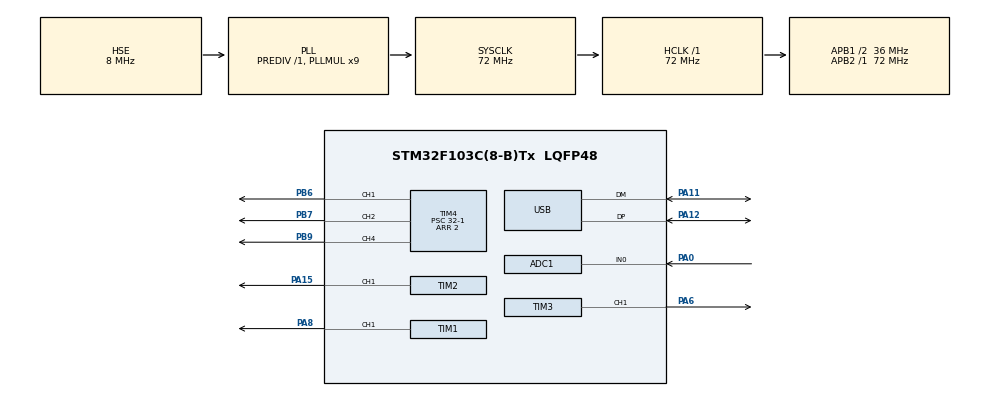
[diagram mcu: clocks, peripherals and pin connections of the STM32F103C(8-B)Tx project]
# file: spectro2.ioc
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ADC1.Channel-4\#ChannelRegularConversion=ADC_CHANNEL_0
ADC1.ContinuousConvMode=DISABLE
ADC1.DataAlign=ADC_DATAALIGN_RIGHT
ADC1.DiscontinuousConvMode=DISABLE
ADC1.EnableAnalogWatchDog=false
ADC1.EnableRegularConversion=ENABLE
ADC1.ExternalTrigConv=ADC_EXTERNALTRIGCONV_T4_CC4
ADC1.ExternalTrigConvEdgeChoice=RISING
ADC1.InjNumberOfConversion=0
ADC1.NbrOfConversion=1
ADC1.NbrOfConversionFlag=1
ADC1.Rank-4\#ChannelRegularConversion=1
ADC1.SamplingTime-4\#ChannelRegularConversion=ADC_SAMPLETIME_1CYCLE_5
ADC1.ScanConvMode=ADC_SCAN_DISABLE
ADC1.master=1
Dma.ADC1.0.Direction=DMA_PERIPH_TO_MEMORY
Dma.ADC1.0.Instance=DMA1_Channel1
Dma.ADC1.0.MemDataAlignment=DMA_MDATAALIGN_HALFWORD
Dma.ADC1.0.MemInc=DMA_MINC_ENABLE
Dma.ADC1.0.Mode=DMA_NORMAL
Dma.ADC1.0.PeriphDataAlignment=DMA_PDATAALIGN_HALFWORD
Dma.ADC1.0.PeriphInc=DMA_PINC_DISABLE
Dma.ADC1.0.Priority=DMA_PRIORITY_LOW
Dma.Request0=ADC1
Mcu.Family=STM32F1
Mcu.Name=STM32F103C(8-B)Tx
Mcu.Package=LQFP48
NVIC.DMA1_Channel1_IRQn=true\:0\:0\:false\:false\:true
NVIC.PriorityGroup=NVIC_PRIORITYGROUP_4
NVIC.USB_LP_CAN1_RX0_IRQn=true\:0\:0\:false\:false\:true
PA0-WKUP.Signal=ADCx_IN0
PA11.Mode=Device
PA11.Signal=USB_DM
PA12.Mode=Device
PA12.Signal=USB_DP
PA15.Signal=S_TIM2_CH1_ETR
PA6.Signal=S_TIM3_CH1
PA8.Signal=S_TIM1_CH1
PB6.Signal=S_TIM4_CH1
PB7.Signal=S_TIM4_CH2
PB9.Signal=S_TIM4_CH4
PD0-OSC_IN.Mode=HSE-External-Oscillator
PD0-OSC_IN.Signal=RCC_OSC_IN
PD1-OSC_OUT.Mode=HSE-External-Oscillator
PD1-OSC_OUT.Signal=RCC_OSC_OUT
ProjectManager.HeapSize=0x200
ProjectManager.StackSize=0x400
ProjectManager.TargetToolchain=MDK-ARM V5
RCC.ADCPresc=RCC_ADCPCLK2_DIV8
RCC.AHBFreq_Value=72000000
RCC.APB1CLKDivider=RCC_HCLK_DIV2
RCC.APB1Freq_Value=36000000
RCC.APB1TimFreq_Value=72000000
RCC.APB2Freq_Value=72000000
RCC.APB2TimFreq_Value=72000000
RCC.HCLKFreq_Value=72000000
RCC.HSIState=RCC_HSI_ON
RCC.PLLMUL=RCC_PLL_MUL9
RCC.PLLSourceVirtual=RCC_PLLSOURCE_HSE
RCC.SYSCLKFreq_VALUE=72000000
RCC.SYSCLKSource=RCC_SYSCLKSOURCE_PLLCLK
RCC.USBFreq_Value=48000000
RCC.USBPrescaler=RCC_USBCLKSOURCE_PLL_DIV1_5
SH.ADCx_IN0.0=ADC1_IN0,IN0
SH.S_TIM1_CH1.0=TIM1_CH1,PWM Generation1 CH1
SH.S_TIM2_CH1_ETR.0=TIM2_CH1,PWM Generation1 CH1
SH.S_TIM3_CH1.0=TIM3_CH1,PWM Generation1 CH1
SH.S_TIM4_CH1.0=TIM4_CH1,PWM Generation1 CH1
SH.S_TIM4_CH2.0=TIM4_CH2,PWM Generation2 CH2
SH.S_TIM4_CH4.0=TIM4_CH4,Forced Output4 CH4
TIM1.ClockDivision=TIM_CLOCKDIVISION_DIV1
TIM1.Period=2000-1
TIM1.Prescaler=36000-1
TIM1.Pulse-PWM\ Generation1\ CH1=50
TIM1.TIM_MasterOutputTrigger=TIM_TRGO_UPDATE
TIM1.TIM_MasterSlaveMode=TIM_MASTERSLAVEMODE_ENABLE
TIM2.OCPolarity_1=TIM_OCPOLARITY_LOW
TIM2.Period=200-1
TIM2.Prescaler=36-1
TIM2.Pulse-PWM\ Generation1\ CH1=50
TIM2.TIM_MasterOutputTrigger=TIM_TRGO_UPDATE
TIM2.TIM_MasterSlaveMode=TIM_MASTERSLAVEMODE_ENABLE
TIM3.OCPolarity_1=TIM_OCPOLARITY_LOW
TIM3.Period=200-1
TIM3.Prescaler=36-1
TIM3.Pulse-PWM\ Generation1\ CH1=50
TIM3.TIM_MasterOutputTrigger=TIM_TRGO_OC1
TIM3.TIM_MasterSlaveMode=TIM_MASTERSLAVEMODE_ENABLE
TIM4.Channel-Forced\ Output4\ CH4=TIM_CHANNEL_4
TIM4.Channel-PWM\ Generation2\ CH2=TIM_CHANNEL_2
TIM4.Period=2
TIM4.Prescaler=32-1
TIM4.Pulse-PWM\ Generation1\ CH1=1
USB_DEVICE.CLASS_NAME_FS=CDC
USB_DEVICE.MANUFACTURER_STRING=kvaoar
USB_DEVICE.PRODUCT_STRING_CDC_FS=SPECTRO
USB_DEVICE.USBD_HandleTypeDef=hUsbDeviceFS
USB_DEVICE.VirtualMode=Cdc
USB_DEVICE.VirtualModeFS=Cdc_FS
VP_TIM1_VS_ClockSourceINT.Mode=Internal
VP_TIM2_VS_ClockSourceINT.Mode=Internal
VP_TIM2_VS_ClockSourceITR.Mode=TriggerSource_ITR0
VP_TIM2_VS_ControllerModeTrigger.Mode=Trigger Mode
VP_TIM2_VS_OPM.Mode=OPM_bit
VP_TIM3_VS_ClockSourceITR.Mode=TriggerSource_ITR1
VP_TIM3_VS_ControllerModeTrigger.Mode=Trigger Mode
VP_TIM3_VS_OPM.Mode=OPM_bit
VP_TIM4_VS_ClockSourceITR.Mode=TriggerSource_ITR2
VP_TIM4_VS_ControllerModeGated.Mode=Gated Mode
VP_USB_DEVICE_VS_USB_DEVICE_CDC_FS.Mode=CDC_FS
board=spectro2

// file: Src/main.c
/**
  ******************************************************************************
  * File Name          : main.c
  * Description        : Main program body
  ******************************************************************************
  *
  * COPYRIGHT(c) 2016 STMicroelectronics
  *
  * Redistribution and use in source and binary forms, with or without modification,
  * are permitted provided that the following conditions are met:
  *   1. Redistributions of source code must retain the above copyright notice,
  *      this list of conditions and the following disclaimer.
  *   2. Redistributions in binary form must reproduce the above copyright notice,
  *      this list of conditions and the following disclaimer in the documentation
  *      and/or other materials provided with the distribution.
  *   3. Neither the name of STMicroelectronics nor the names of its contributors
  *      may be used to endorse or promote products derived from this software
  *      without specific prior written permission.
  *
  * THIS SOFTWARE IS PROVIDED BY THE COPYRIGHT HOLDERS AND CONTRIBUTORS "AS IS"
  * AND ANY EXPRESS OR IMPLIED WARRANTIES, INCLUDING, BUT NOT LIMITED TO, THE
  * IMPLIED WARRANTIES OF MERCHANTABILITY AND FITNESS FOR A PARTICULAR PURPOSE ARE
  * DISCLAIMED. IN NO EVENT SHALL THE COPYRIGHT HOLDER OR CONTRIBUTORS BE LIABLE
  * FOR ANY DIRECT, INDIRECT, INCIDENTAL, SPECIAL, EXEMPLARY, OR CONSEQUENTIAL
  * DAMAGES (INCLUDING, BUT NOT LIMITED TO, PROCUREMENT OF SUBSTITUTE GOODS OR
  * SERVICES; LOSS OF USE, DATA, OR PROFITS; OR BUSINESS INTERRUPTION) HOWEVER
  * CAUSED AND ON ANY THEORY OF LIABILITY, WHETHER IN CONTRACT, STRICT LIABILITY,
  * OR TORT (INCLUDING NEGLIGENCE OR OTHERWISE) ARISING IN ANY WAY OUT OF THE USE
  * OF THIS SOFTWARE, EVEN IF ADVISED OF THE POSSIBILITY OF SUCH DAMAGE.
  *
  ******************************************************************************
  */
#include "stm32f1xx_hal.h"
#include "usb_device.h"
#include "usbd_cdc_if.h"

ADC_HandleTypeDef hadc1;
DMA_HandleTypeDef hdma_adc1;

TIM_HandleTypeDef htim1;
TIM_HandleTypeDef htim2;
TIM_HandleTypeDef htim3;
TIM_HandleTypeDef htim4;

/* USER CODE BEGIN PV */
/* Private variables ---------------------------------------------------------*/

/* USER CODE END PV */

void SystemClock_Config(void);
static void MX_GPIO_Init(void);
static void MX_DMA_Init(void);
static void MX_TIM1_Init(void);
static void MX_TIM2_Init(void);
static void MX_TIM3_Init(void);
static void MX_TIM4_Init(void);
static void MX_ADC1_Init(void);

void HAL_TIM_MspPostInit(TIM_HandleTypeDef *htim);
uint16_t buf[3000];

/* USER CODE BEGIN PFP */
/* Private function prototypes -----------------------------------------------*/

/* USER CODE END PFP */

/* USER CODE BEGIN 0 */
const int N = 4;
const int Tpixel = 10;//us
/* USER CODE END 0 */

int main(void)
{

  /* MCU Configuration----------------------------------------------------------*/

  /* Reset of all peripherals, Initializes the Flash interface and the Systick. */
  HAL_Init();

  /* Configure the system clock */
  SystemClock_Config();
MX_USB_DEVICE_Init();
  /* Initialize all configured peripherals */
  MX_GPIO_Init();
  MX_DMA_Init();
  MX_TIM1_Init();

  MX_TIM2_Init();
  MX_TIM3_Init();
  MX_TIM4_Init();
  MX_ADC1_Init();

  /* USER CODE BEGIN 2 */
//HAL_TIM_Base_Start(&htim1);
//HAL_TIM_Base_Start(&htim2);

//HAL_ADC_Start_DMA(&hadc1,(uint32_t*)buf,3000);
HAL_TIM_PWM_Start(&htim1, TIM_CHANNEL_1);
HAL_TIM_PWM_Start(&htim2, TIM_CHANNEL_1);
HAL_TIM_PWM_Start(&htim3, TIM_CHANNEL_1);
HAL_TIM_PWM_Start(&htim4, TIM_CHANNEL_1);
HAL_TIM_PWM_Start(&htim4, TIM_CHANNEL_2);

HAL_Delay(1000);
  /* USER CODE END 2 */

  /* Infinite loop */
  while (1)
  {

	//	for(int i = 0; i < 3000; i++)buf[i]=i;
HAL_DMA_PollForTransfer(hadc1.DMA_Handle,HAL_DMA_FULL_TRANSFER,1000);
uint16_t mark =0xABBA;
CDC_Transmit_FS((uint8_t*)&mark,2);
			HAL_Delay(10);
for(int i = 0; i < 3; i++){
CDC_Transmit_FS((uint8_t*)&buf[1000*i],2000);
	HAL_Delay(10);
}
HAL_Delay(100);
HAL_ADC_Start_DMA(&hadc1,(uint32_t*)buf,3000);

  }

}

/** System Clock Configuration
*/
void SystemClock_Config(void)
{

  RCC_OscInitTypeDef RCC_OscInitStruct;
  RCC_ClkInitTypeDef RCC_ClkInitStruct;
  RCC_PeriphCLKInitTypeDef PeriphClkInit;

  RCC_OscInitStruct.OscillatorType = RCC_OSCILLATORTYPE_HSE;
  RCC_OscInitStruct.HSEState = RCC_HSE_ON;
  RCC_OscInitStruct.HSEPredivValue = RCC_HSE_PREDIV_DIV1;
  RCC_OscInitStruct.PLL.PLLState = RCC_PLL_ON;
  RCC_OscInitStruct.PLL.PLLSource = RCC_PLLSOURCE_HSE;
  RCC_OscInitStruct.PLL.PLLMUL = RCC_PLL_MUL9;
  HAL_RCC_OscConfig(&RCC_OscInitStruct);

  RCC_ClkInitStruct.ClockType = RCC_CLOCKTYPE_HCLK|RCC_CLOCKTYPE_SYSCLK
                              |RCC_CLOCKTYPE_PCLK1|RCC_CLOCKTYPE_PCLK2;
  RCC_ClkInitStruct.SYSCLKSource = RCC_SYSCLKSOURCE_PLLCLK;
  RCC_ClkInitStruct.AHBCLKDivider = RCC_SYSCLK_DIV1;
  RCC_ClkInitStruct.APB1CLKDivider = RCC_HCLK_DIV2;
  RCC_ClkInitStruct.APB2CLKDivider = RCC_HCLK_DIV1;
  HAL_RCC_ClockConfig(&RCC_ClkInitStruct, FLASH_LATENCY_2);

  PeriphClkInit.PeriphClockSelection = RCC_PERIPHCLK_ADC|RCC_PERIPHCLK_USB;
  PeriphClkInit.AdcClockSelection = RCC_ADCPCLK2_DIV8;
  PeriphClkInit.UsbClockSelection = RCC_USBCLKSOURCE_PLL_DIV1_5;
  HAL_RCCEx_PeriphCLKConfig(&PeriphClkInit);

  HAL_SYSTICK_Config(HAL_RCC_GetHCLKFreq()/1000);

  HAL_SYSTICK_CLKSourceConfig(SYSTICK_CLKSOURCE_HCLK);

  /* SysTick_IRQn interrupt configuration */
  HAL_NVIC_SetPriority(SysTick_IRQn, 0, 0);
}

/* ADC1 init function */
void MX_ADC1_Init(void)
{

  ADC_ChannelConfTypeDef sConfig;

    /**Common config
    */
  hadc1.Instance = ADC1;
  hadc1.Init.ScanConvMode = ADC_SCAN_DISABLE;
  hadc1.Init.ContinuousConvMode = DISABLE;
  hadc1.Init.DiscontinuousConvMode = DISABLE;
  hadc1.Init.ExternalTrigConv = ADC_EXTERNALTRIGCONV_EXT_IT11;
  hadc1.Init.DataAlign = ADC_DATAALIGN_RIGHT;
  hadc1.Init.NbrOfConversion = 1;
  HAL_ADC_Init(&hadc1);

    /**Configure Regular Channel
    */
  sConfig.Channel = ADC_CHANNEL_1;
  sConfig.Rank = 1;
  sConfig.SamplingTime = ADC_SAMPLETIME_1CYCLE_5;
  HAL_ADC_ConfigChannel(&hadc1, &sConfig);

}

/* TIM1 init function */
void MX_TIM1_Init(void)
{

  TIM_ClockConfigTypeDef sClockSourceConfig;
  TIM_MasterConfigTypeDef sMasterConfig;
  TIM_BreakDeadTimeConfigTypeDef sBreakDeadTimeConfig;
  TIM_OC_InitTypeDef sConfigOC;

  htim1.Instance = TIM1;
  htim1.Init.Prescaler = 360-1;
  htim1.Init.CounterMode = TIM_COUNTERMODE_UP;
  htim1.Init.Period = 10000-1;
  htim1.Init.ClockDivision = TIM_CLOCKDIVISION_DIV1;
  htim1.Init.RepetitionCounter = 0;
  HAL_TIM_Base_Init(&htim1);

  sClockSourceConfig.ClockSource = TIM_CLOCKSOURCE_INTERNAL;
  HAL_TIM_ConfigClockSource(&htim1, &sClockSourceConfig);

  HAL_TIM_PWM_Init(&htim1);

  sMasterConfig.MasterOutputTrigger = TIM_TRGO_UPDATE;
  sMasterConfig.MasterSlaveMode = TIM_MASTERSLAVEMODE_ENABLE;
  HAL_TIMEx_MasterConfigSynchronization(&htim1, &sMasterConfig);

  sBreakDeadTimeConfig.OffStateRunMode = TIM_OSSR_DISABLE;
  sBreakDeadTimeConfig.OffStateIDLEMode = TIM_OSSI_DISABLE;
  sBreakDeadTimeConfig.LockLevel = TIM_LOCKLEVEL_OFF;
  sBreakDeadTimeConfig.DeadTime = 0;
  sBreakDeadTimeConfig.BreakState = TIM_BREAK_DISABLE;
  sBreakDeadTimeConfig.BreakPolarity = TIM_BREAKPOLARITY_HIGH;
  sBreakDeadTimeConfig.AutomaticOutput = TIM_AUTOMATICOUTPUT_DISABLE;
  HAL_TIMEx_ConfigBreakDeadTime(&htim1, &sBreakDeadTimeConfig);

  sConfigOC.OCMode = TIM_OCMODE_PWM1;
  sConfigOC.Pulse = 1;
  sConfigOC.OCPolarity = TIM_OCPOLARITY_HIGH;
  sConfigOC.OCNPolarity = TIM_OCNPOLARITY_HIGH;
  sConfigOC.OCFastMode = TIM_OCFAST_DISABLE;
  sConfigOC.OCIdleState = TIM_OCIDLESTATE_RESET;
  sConfigOC.OCNIdleState = TIM_OCNIDLESTATE_RESET;
  HAL_TIM_PWM_ConfigChannel(&htim1, &sConfigOC, TIM_CHANNEL_1);

  HAL_TIM_MspPostInit(&htim1);

}

/* TIM2 init function */
void MX_TIM2_Init(void)
{

  TIM_ClockConfigTypeDef sClockSourceConfig;
  TIM_SlaveConfigTypeDef sSlaveConfig;
  TIM_MasterConfigTypeDef sMasterConfig;
  TIM_OC_InitTypeDef sConfigOC;

  htim2.Instance = TIM2;
  htim2.Init.Prescaler = 36-1;
  htim2.Init.CounterMode = TIM_COUNTERMODE_UP;
  htim2.Init.Period = 20-1;
  htim2.Init.ClockDivision = TIM_CLOCKDIVISION_DIV1;
  HAL_TIM_Base_Init(&htim2);

  sClockSourceConfig.ClockSource = TIM_CLOCKSOURCE_INTERNAL;
  HAL_TIM_ConfigClockSource(&htim2, &sClockSourceConfig);

  HAL_TIM_PWM_Init(&htim2);

  HAL_TIM_OnePulse_Init(&htim2, TIM_OPMODE_SINGLE);

  sSlaveConfig.SlaveMode = TIM_SLAVEMODE_TRIGGER;
  sSlaveConfig.InputTrigger = TIM_TS_ITR0;
  HAL_TIM_SlaveConfigSynchronization(&htim2, &sSlaveConfig);

  sMasterConfig.MasterOutputTrigger = TIM_TRGO_UPDATE;
  sMasterConfig.MasterSlaveMode = TIM_MASTERSLAVEMODE_ENABLE;
  HAL_TIMEx_MasterConfigSynchronization(&htim2, &sMasterConfig);

  sConfigOC.OCMode = TIM_OCMODE_PWM1;
  sConfigOC.Pulse = 10-2;
  sConfigOC.OCPolarity = TIM_OCPOLARITY_LOW;
  sConfigOC.OCFastMode = TIM_OCFAST_DISABLE;
  HAL_TIM_PWM_ConfigChannel(&htim2, &sConfigOC, TIM_CHANNEL_1);

  HAL_TIM_MspPostInit(&htim2);

}

/* TIM3 init function */
void MX_TIM3_Init(void)
{

  TIM_SlaveConfigTypeDef sSlaveConfig;
  TIM_MasterConfigTypeDef sMasterConfig;
  TIM_OC_InitTypeDef sConfigOC;

  htim3.Instance = TIM3;
  htim3.Init.Prescaler = 36-1;
  htim3.Init.CounterMode = TIM_COUNTERMODE_DOWN;
  htim3.Init.Period = (8*3000 +1)-1;
  htim3.Init.ClockDivision = TIM_CLOCKDIVISION_DIV1;
  HAL_TIM_Base_Init(&htim3);

  HAL_TIM_PWM_Init(&htim3);

  HAL_TIM_OnePulse_Init(&htim3, TIM_OPMODE_SINGLE);

  sSlaveConfig.SlaveMode = TIM_SLAVEMODE_TRIGGER;
  sSlaveConfig.InputTrigger = TIM_TS_ITR1;
  HAL_TIM_SlaveConfigSynchronization(&htim3, &sSlaveConfig);

  sMasterConfig.MasterOutputTrigger = TIM_TRGO_OC1REF;
  sMasterConfig.MasterSlaveMode = TIM_MASTERSLAVEMODE_ENABLE;
  HAL_TIMEx_MasterConfigSynchronization(&htim3, &sMasterConfig);

  sConfigOC.OCMode = TIM_OCMODE_PWM1;
  sConfigOC.Pulse = (8*3000 +1)-2;//2087
  sConfigOC.OCPolarity = TIM_OCPOLARITY_LOW;
  sConfigOC.OCFastMode = TIM_OCFAST_DISABLE;
  HAL_TIM_PWM_ConfigChannel(&htim3, &sConfigOC, TIM_CHANNEL_1);

  HAL_TIM_MspPostInit(&htim3);

}

/* TIM4 init function */
void MX_TIM4_Init(void)
{

  TIM_SlaveConfigTypeDef sSlaveConfig;
  TIM_MasterConfigTypeDef sMasterConfig;
  TIM_OC_InitTypeDef sConfigOC;

  htim4.Instance = TIM4;
  htim4.Init.Prescaler = 36-1;
  htim4.Init.CounterMode = TIM_COUNTERMODE_UP;
  htim4.Init.Period = 8-1;
  htim4.Init.ClockDivision = TIM_CLOCKDIVISION_DIV1;
  HAL_TIM_Base_Init(&htim4);

  HAL_TIM_PWM_Init(&htim4);

  sSlaveConfig.SlaveMode = TIM_SLAVEMODE_GATED;
  sSlaveConfig.InputTrigger = TIM_TS_ITR2;
  HAL_TIM_SlaveConfigSynchronization(&htim4, &sSlaveConfig);

  sMasterConfig.MasterOutputTrigger = TIM_TRGO_OC1;
  sMasterConfig.MasterSlaveMode = TIM_MASTERSLAVEMODE_DISABLE;
  HAL_TIMEx_MasterConfigSynchronization(&htim4, &sMasterConfig);

  sConfigOC.OCMode = TIM_OCMODE_PWM1;
  sConfigOC.Pulse = 4;
  sConfigOC.OCPolarity = TIM_OCPOLARITY_HIGH;
  sConfigOC.OCFastMode = TIM_OCFAST_ENABLE;
  HAL_TIM_PWM_ConfigChannel(&htim4, &sConfigOC, TIM_CHANNEL_1);
  sConfigOC.OCMode = TIM_OCMODE_PWM1;
  sConfigOC.Pulse = 6;
  sConfigOC.OCPolarity = TIM_OCPOLARITY_HIGH;
  sConfigOC.OCFastMode = TIM_OCFAST_ENABLE;
  HAL_TIM_PWM_ConfigChannel(&htim4, &sConfigOC, TIM_CHANNEL_2);
  HAL_TIM_MspPostInit(&htim4);

}

void MX_DMA_Init(void)
{
  /* DMA controller clock enable */
  __HAL_RCC_DMA1_CLK_ENABLE();

  /* DMA interrupt init */
  /* DMA1_Channel1_IRQn interrupt configuration */
  HAL_NVIC_SetPriority(DMA1_Channel1_IRQn, 0, 0);
  HAL_NVIC_EnableIRQ(DMA1_Channel1_IRQn);

}

/** Configure pins as
        * Analog
        * Input
        * Output
        * EVENT_OUT
        * EXTI
*/
void MX_GPIO_Init(void)
{

  /* GPIO Ports Clock Enable */
  __HAL_RCC_GPIOD_CLK_ENABLE();
  __HAL_RCC_GPIOA_CLK_ENABLE();
  __HAL_RCC_GPIOB_CLK_ENABLE();

}

/************************ (C) COPYRIGHT STMicroelectronics *****END OF FILE****/
